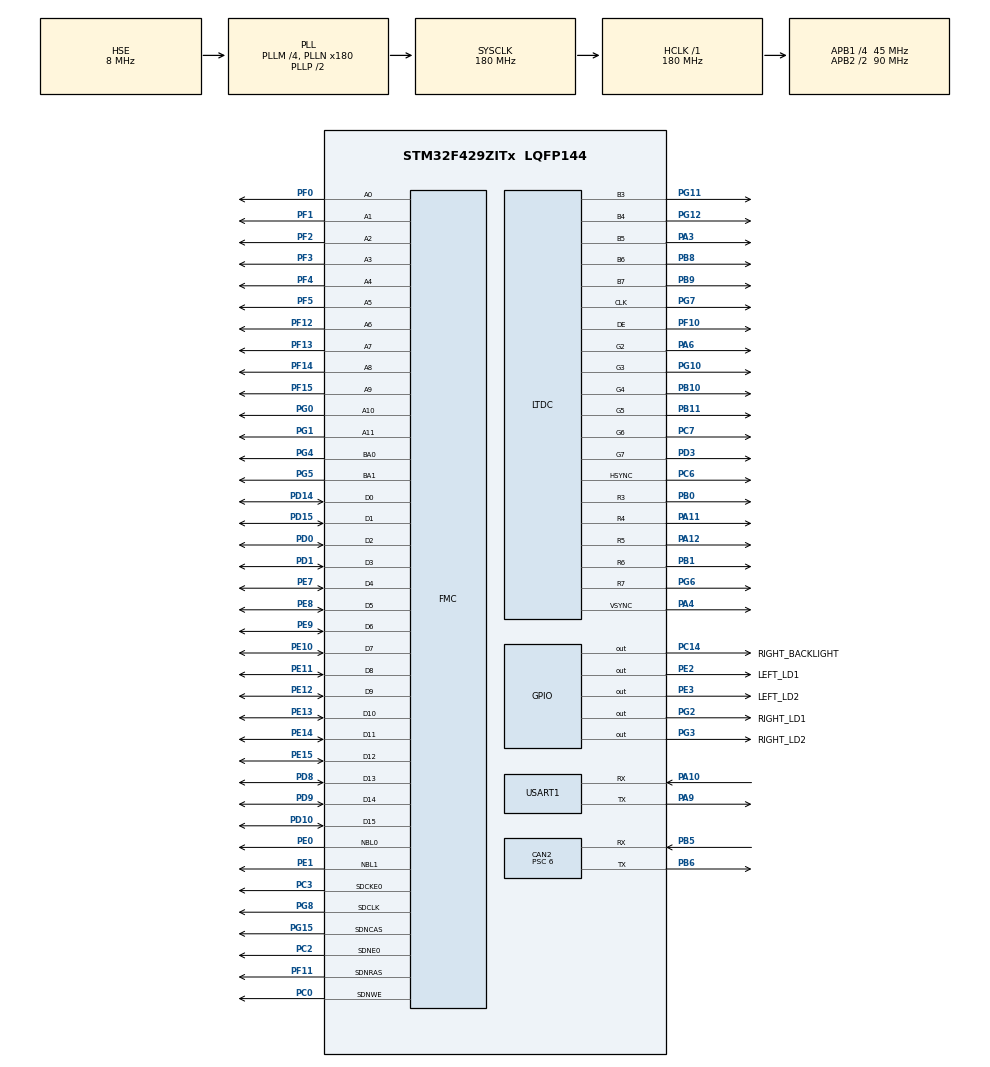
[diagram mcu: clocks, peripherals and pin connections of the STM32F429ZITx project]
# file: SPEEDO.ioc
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CAN2.ABOM=ENABLE
CAN2.BS1=CAN_BS1_12TQ
CAN2.BS2=CAN_BS2_2TQ
CAN2.CalculateTimeQuantum=133.33333333333331
CAN2.Prescaler=6
DMA2D.ColorMode=DMA2D_OUTPUT_RGB565
DMA2D.Mode=DMA2D_R2M
FMC.CASLatency1=FMC_SDRAM_CAS_LATENCY_3
FMC.ExitSelfRefreshDelay1=7
FMC.LoadToActiveDelay1=2
FMC.RPDelay1=2
FMC.RPDelay2=2
FMC.ReadPipeDelay1=FMC_SDRAM_RPIPE_DELAY_1
FMC.ReadPipeDelay2=FMC_SDRAM_RPIPE_DELAY_1
FMC.RowCycleDelay1=7
FMC.RowCycleDelay2=7
FMC.SDClockPeriod1=FMC_SDRAM_CLOCK_PERIOD_2
FMC.SDClockPeriod2=FMC_SDRAM_CLOCK_PERIOD_2
FMC.SelfRefreshTime1=4
FMC.WriteRecoveryTime1=2
FREERTOS.INCLUDE_vTaskDelayUntil=1
FREERTOS.Mutexes01=CanTxMutex,Dynamic,NULL;LogMutex,Dynamic,NULL
FREERTOS.Tasks01=ManagerTask,55,128,StartManagerTask,Default,NULL,Dynamic,NULL,NULL;DisplayTask,32,256,StartDisplayTask,As weak,NULL,Dynamic,NULL,NULL;CanTxTask,24,128,StartCanTxTask,Default,NULL,Dynamic,NULL,NULL;CanRxTask,40,128,StartCanRxTask,Default,NULL,Dynamic,NULL,NULL
FREERTOS.configTIMER_TASK_PRIORITY=6
FREERTOS.configTIMER_TASK_STACK_DEPTH=128
FREERTOS.configTOTAL_HEAP_SIZE=22360
FREERTOS.configUSE_COUNTING_SEMAPHORES=1
FREERTOS.configUSE_RECURSIVE_MUTEXES=1
FREERTOS.configUSE_TIMERS=0
IWDG.Prescaler=IWDG_PRESCALER_16
LTDC.ActiveH=240
LTDC.ActiveW=320
LTDC.Alpha_L0=255
LTDC.Alpha_L1=255
LTDC.BlendingFactor1_L0=LTDC_BLENDING_FACTOR1_PAxCA
LTDC.BlendingFactor1_L1=LTDC_BLENDING_FACTOR1_PAxCA
LTDC.BlendingFactor2_L0=LTDC_BLENDING_FACTOR2_PAxCA
LTDC.BlendingFactor2_L1=LTDC_BLENDING_FACTOR2_PAxCA
LTDC.FBStartAdress_L0=0xC0000000
LTDC.FBStartAdress_L1=0xC0400000
LTDC.HBP=43
LTDC.HFP=8
LTDC.HSync=4
LTDC.ImageHeight_L0=240
LTDC.ImageHeight_L1=240
LTDC.ImageWidth_L0=320
LTDC.ImageWidth_L1=320
LTDC.PixelFormat_L0=LTDC_PIXEL_FORMAT_RGB565
LTDC.PixelFormat_L1=LTDC_PIXEL_FORMAT_ARGB1555
LTDC.VBP=12
LTDC.VFP=8
LTDC.VSync=4
LTDC.WindowX1_L0=320
LTDC.WindowX1_L1=320
LTDC.WindowY1_L0=240
LTDC.WindowY1_L1=240
Mcu.Family=STM32F4
Mcu.Name=STM32F429ZITx
Mcu.Package=LQFP144
NVIC.CAN2_RX0_IRQn=true\:5\:0\:false\:false\:true\:true\:true\:true
NVIC.DMA2D_IRQn=true\:5\:0\:false\:false\:false\:true\:true\:false
NVIC.LTDC_IRQn=true\:5\:0\:false\:false\:true\:true\:true\:true
NVIC.PriorityGroup=NVIC_PRIORITYGROUP_4
NVIC.TIM6_DAC_IRQn=true\:0\:0\:false\:false\:true\:false\:false\:true
NVIC.TimeBase=TIM6_DAC_IRQn
NVIC.TimeBaseIP=TIM6
NVIC.USART1_IRQn=true\:5\:0\:false\:false\:true\:true\:true\:true
PA10.Mode=Asynchronous
PA10.Signal=USART1_RX
PA11.Mode=RGB565
PA11.Signal=LTDC_R4
PA12.Mode=RGB565
PA12.Signal=LTDC_R5
PA13.Mode=Trace_Asynchronous_SW
PA13.Signal=SYS_JTMS-SWDIO
PA14.Mode=Trace_Asynchronous_SW
PA14.Signal=SYS_JTCK-SWCLK
PA3.Mode=RGB565
PA3.Signal=LTDC_B5
PA4.Mode=RGB565
PA4.Signal=LTDC_VSYNC
PA6.Mode=RGB565
PA6.Signal=LTDC_G2
PA9.Mode=Asynchronous
PA9.Signal=USART1_TX
PB0.Mode=RGB565
PB0.Signal=LTDC_R3
PB1.Mode=RGB565
PB1.Signal=LTDC_R6
PB10.Mode=RGB565
PB10.Signal=LTDC_G4
PB11.Mode=RGB565
PB11.Signal=LTDC_G5
PB3.Mode=Trace_Asynchronous_SW
PB3.Signal=SYS_JTDO-SWO
PB5.Mode=Slave
PB5.Signal=CAN2_RX
PB6.Mode=Slave
PB6.Signal=CAN2_TX
PB8.Mode=RGB565
PB8.Signal=LTDC_B6
PB9.Mode=RGB565
PB9.Signal=LTDC_B7
PC0.Signal=FMC_SDNWE
PC14/OSC32_IN.GPIO_Label=RIGHT_BACKLIGHT
PC14/OSC32_IN.Signal=GPIO_Output
PC2.Mode=SdramChipSelect1_1
PC2.Signal=FMC_SDNE0
PC3.Mode=SdramChipSelect1_1
PC3.Signal=FMC_SDCKE0
PC6.Mode=RGB565
PC6.Signal=LTDC_HSYNC
PC7.Mode=RGB565
PC7.Signal=LTDC_G6
PD0.Signal=FMC_D2_DA2
PD1.Signal=FMC_D3_DA3
PD10.Signal=FMC_D15_DA15
PD14.Signal=FMC_D0_DA0
PD15.Signal=FMC_D1_DA1
PD3.Mode=RGB565
PD3.Signal=LTDC_G7
PD8.Signal=FMC_D13_DA13
PD9.Signal=FMC_D14_DA14
PE0.Signal=FMC_NBL0
PE1.Signal=FMC_NBL1
PE10.Signal=FMC_D7_DA7
PE11.Signal=FMC_D8_DA8
PE12.Signal=FMC_D9_DA9
PE13.Signal=FMC_D10_DA10
PE14.Signal=FMC_D11_DA11
PE15.Signal=FMC_D12_DA12
PE2.GPIO_Label=LEFT_LD1
PE2.Signal=GPIO_Output
PE3.GPIO_Label=LEFT_LD2
PE3.Signal=GPIO_Output
PE7.Signal=FMC_D4_DA4
PE8.Signal=FMC_D5_DA5
PE9.Signal=FMC_D6_DA6
PF0.Signal=FMC_A0
PF1.Signal=FMC_A1
PF10.Mode=RGB565
PF10.Signal=LTDC_DE
PF11.Signal=FMC_SDNRAS
PF12.Signal=FMC_A6
PF13.Signal=FMC_A7
PF14.Signal=FMC_A8
PF15.Signal=FMC_A9
PF2.Signal=FMC_A2
PF3.Signal=FMC_A3
PF4.Signal=FMC_A4
PF5.Signal=FMC_A5
PG0.Signal=FMC_A10
PG1.Signal=FMC_A11
PG10.Mode=RGB565
PG10.Signal=LTDC_G3
PG11.Mode=RGB565
PG11.Signal=LTDC_B3
PG12.Mode=RGB565
PG12.Signal=LTDC_B4
PG15.Signal=FMC_SDNCAS
PG2.GPIO_Label=RIGHT_LD1
PG2.Signal=GPIO_Output
PG3.GPIO_Label=RIGHT_LD2
PG3.Signal=GPIO_Output
PG4.Signal=FMC_A14_BA0
PG5.Signal=FMC_A15_BA1
PG6.Mode=RGB565
PG6.Signal=LTDC_R7
PG7.Mode=RGB565
PG7.Signal=LTDC_CLK
PG8.Signal=FMC_SDCLK
PH0/OSC_IN.Mode=HSE-External-Oscillator
PH0/OSC_IN.Signal=RCC_OSC_IN
PH1/OSC_OUT.Mode=HSE-External-Oscillator
PH1/OSC_OUT.Signal=RCC_OSC_OUT
ProjectManager.HeapSize=0x200
ProjectManager.StackSize=0x400
ProjectManager.TargetToolchain=STM32CubeIDE
RCC.48MHZClocksFreq_Value=90000000
RCC.AHBFreq_Value=180000000
RCC.APB1CLKDivider=RCC_HCLK_DIV4
RCC.APB1Freq_Value=45000000
RCC.APB1TimFreq_Value=90000000
RCC.APB2CLKDivider=RCC_HCLK_DIV2
RCC.APB2Freq_Value=90000000
RCC.APB2TimFreq_Value=180000000
RCC.CortexFreq_Value=180000000
RCC.HCLKFreq_Value=180000000
RCC.HSE_VALUE=8000000
RCC.HSI_VALUE=16000000
RCC.LSE_VALUE=32768
RCC.PLLM=4
RCC.PLLN=180
RCC.PLLSAIDivR=RCC_PLLSAIDIVR_4
RCC.PLLSAIN=60
RCC.PLLSAIR=5
RCC.PLLSourceVirtual=RCC_PLLSOURCE_HSE
RCC.PWREXT_OverDrive=PWREXT_OverDrive_ACTIVATED
RCC.PWR_Regulator_Voltage_Scale=PWR_REGULATOR_VOLTAGE_SCALE1
RCC.SYSCLKFreq_VALUE=180000000
RCC.SYSCLKSource=RCC_SYSCLKSOURCE_PLLCLK
RCC.VCOOutputFreq_Value=360000000
SH.FMC_A0.0=FMC_A0,12b-sda1
SH.FMC_A1.0=FMC_A1,12b-sda1
SH.FMC_A10.0=FMC_A10,12b-sda1
SH.FMC_A11.0=FMC_A11,12b-sda1
SH.FMC_A14_BA0.0=FMC_BA0,FourSdramBanks1
SH.FMC_A15_BA1.0=FMC_BA1,FourSdramBanks1
SH.FMC_A2.0=FMC_A2,12b-sda1
SH.FMC_A3.0=FMC_A3,12b-sda1
SH.FMC_A4.0=FMC_A4,12b-sda1
SH.FMC_A5.0=FMC_A5,12b-sda1
SH.FMC_A6.0=FMC_A6,12b-sda1
SH.FMC_A7.0=FMC_A7,12b-sda1
SH.FMC_A8.0=FMC_A8,12b-sda1
SH.FMC_A9.0=FMC_A9,12b-sda1
SH.FMC_D0_DA0.0=FMC_D0,sd-16b-d1
SH.FMC_D10_DA10.0=FMC_D10,sd-16b-d1
SH.FMC_D11_DA11.0=FMC_D11,sd-16b-d1
SH.FMC_D12_DA12.0=FMC_D12,sd-16b-d1
SH.FMC_D13_DA13.0=FMC_D13,sd-16b-d1
SH.FMC_D14_DA14.0=FMC_D14,sd-16b-d1
SH.FMC_D15_DA15.0=FMC_D15,sd-16b-d1
SH.FMC_D1_DA1.0=FMC_D1,sd-16b-d1
SH.FMC_D2_DA2.0=FMC_D2,sd-16b-d1
SH.FMC_D3_DA3.0=FMC_D3,sd-16b-d1
SH.FMC_D4_DA4.0=FMC_D4,sd-16b-d1
SH.FMC_D5_DA5.0=FMC_D5,sd-16b-d1
SH.FMC_D6_DA6.0=FMC_D6,sd-16b-d1
SH.FMC_D7_DA7.0=FMC_D7,sd-16b-d1
SH.FMC_D8_DA8.0=FMC_D8,sd-16b-d1
SH.FMC_D9_DA9.0=FMC_D9,sd-16b-d1
SH.FMC_NBL0.0=FMC_NBL0,Sd2ByteEnable1
SH.FMC_NBL1.0=FMC_NBL1,Sd2ByteEnable1
SH.FMC_SDCLK.0=FMC_SDCLK,12b-sda1
SH.FMC_SDNCAS.0=FMC_SDNCAS,12b-sda1
SH.FMC_SDNRAS.0=FMC_SDNRAS,12b-sda1
SH.FMC_SDNWE.0=FMC_SDNWE,12b-sda1
USART1.VirtualMode=VM_ASYNC
VP_CRC_VS_CRC.Mode=CRC_Activate
VP_DMA2D_VS_DMA2D.Mode=DMA2D_Activate
VP_FREERTOS_VS_CMSIS_V2.Mode=CMSIS_V2
VP_IWDG_VS_IWDG.Mode=IWDG_Activate
VP_SYS_VS_tim6.Mode=TIM6
board=custom

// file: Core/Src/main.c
/* USER CODE BEGIN Header */
/**
 ******************************************************************************
 * @file           : main.c
 * @brief          : Main program body
 ******************************************************************************
 * @attention
 *
 * <h2><center>&copy; Copyright (c) 2020 STMicroelectronics.
 * All rights reserved.</center></h2>
 *
 * This software component is licensed by ST under BSD 3-Clause license,
 * the "License"; You may not use this file except in compliance with the
 * License. You may obtain a copy of the License at:
 *                        opensource.org/licenses/BSD-3-Clause
 *
 ******************************************************************************
 */
/* USER CODE END Header */

#include "main.h"
#include "cmsis_os.h"

/* USER CODE BEGIN Includes */
#include "Libs/_guiapp.h"
#include "Drivers/_stemwin.h"
#include "Drivers/_canbus.h"
#include "Nodes/HMI1.h"
#include "Nodes/VCU.h"
/* USER CODE END Includes */

CAN_HandleTypeDef hcan2;

CRC_HandleTypeDef hcrc;

DMA2D_HandleTypeDef hdma2d;

IWDG_HandleTypeDef hiwdg;

LTDC_HandleTypeDef hltdc;

UART_HandleTypeDef huart1;

SDRAM_HandleTypeDef hsdram1;

/* Definitions for ManagerTask */
osThreadId_t ManagerTaskHandle;
const osThreadAttr_t ManagerTask_attributes = {
		.name = "ManagerTask",
		.priority = (osPriority_t) osPriorityRealtime7,
		.stack_size = 128 * 4
};
/* Definitions for DisplayTask */
osThreadId_t DisplayTaskHandle;
const osThreadAttr_t DisplayTask_attributes = {
		.name = "DisplayTask",
		.priority = (osPriority_t) osPriorityAboveNormal,
		.stack_size = 256 * 4
};
/* Definitions for CanTxTask */
osThreadId_t CanTxTaskHandle;
const osThreadAttr_t CanTxTask_attributes = {
		.name = "CanTxTask",
		.priority = (osPriority_t) osPriorityNormal,
		.stack_size = 128 * 4
};
/* Definitions for CanRxTask */
osThreadId_t CanRxTaskHandle;
const osThreadAttr_t CanRxTask_attributes = {
		.name = "CanRxTask",
		.priority = (osPriority_t) osPriorityHigh,
		.stack_size = 128 * 4
};
/* Definitions for CanTxMutex */
osMutexId_t CanTxMutexHandle;
const osMutexAttr_t CanTxMutex_attributes = {
		.name = "CanTxMutex"
};
/* Definitions for LogMutex */
osMutexId_t LogMutexHandle;
const osMutexAttr_t LogMutex_attributes = {
		.name = "LogMutex"
};
/* USER CODE BEGIN PV */
osEventFlagsId_t GlobalEventHandle;
/* USER CODE END PV */

void SystemClock_Config(void);
static void MX_GPIO_Init(void);
static void MX_CAN2_Init(void);
static void MX_CRC_Init(void);
void MX_DMA2D_Init(void);
void MX_FMC_Init(void);
static void MX_IWDG_Init(void);
void MX_LTDC_Init(void);
static void MX_USART1_UART_Init(void);
void StartManagerTask(void *argument);
void StartDisplayTask(void *argument);
void StartCanTxTask(void *argument);
void StartCanRxTask(void *argument);

/* USER CODE BEGIN 0 */
extern hmi1_t HMI1;
extern vcu_t VCU;
/* USER CODE END 0 */

int main(void)
{

	/* MCU Configuration--------------------------------------------------------*/

	/* Reset of all peripherals, Initializes the Flash interface and the Systick. */
	HAL_Init();

	/* Configure the system clock */
	SystemClock_Config();

	/* Initialize all configured peripherals */
	MX_GPIO_Init();
	MX_CAN2_Init();
	MX_CRC_Init();
	MX_IWDG_Init();
	MX_USART1_UART_Init();
	/* USER CODE BEGIN 2 */
	CANBUS_Init();
	GRAPHICS_HW_Init();
	GRAPHICS_Init();
	/* USER CODE END 2 */

	/* Init scheduler */
	osKernelInitialize();
	/* Create the mutex(es) */
	/* creation of CanTxMutex */
	CanTxMutexHandle = osMutexNew(&CanTxMutex_attributes);

	/* creation of LogMutex */
	LogMutexHandle = osMutexNew(&LogMutex_attributes);

	/* USER CODE BEGIN RTOS_QUEUES */
	/* add queues, ... */
	GlobalEventHandle = osEventFlagsNew(NULL);
	/* USER CODE END RTOS_QUEUES */

	/* Create the thread(s) */
	/* creation of ManagerTask */
	ManagerTaskHandle = osThreadNew(StartManagerTask, NULL, &ManagerTask_attributes);

	/* creation of DisplayTask */
	DisplayTaskHandle = osThreadNew(StartDisplayTask, NULL, &DisplayTask_attributes);

	/* creation of CanTxTask */
	CanTxTaskHandle = osThreadNew(StartCanTxTask, NULL, &CanTxTask_attributes);

	/* creation of CanRxTask */
	CanRxTaskHandle = osThreadNew(StartCanRxTask, NULL, &CanRxTask_attributes);

	/* Start scheduler */
	osKernelStart();

	/* We should never get here as control is now taken by the scheduler */
	/* Infinite loop */
	while (1)
	{

	}
}

void SystemClock_Config(void)
{
	RCC_OscInitTypeDef RCC_OscInitStruct = { 0 };
	RCC_ClkInitTypeDef RCC_ClkInitStruct = { 0 };
	RCC_PeriphCLKInitTypeDef PeriphClkInitStruct = { 0 };

	/** Configure the main internal regulator output voltage
	 */
	__HAL_RCC_PWR_CLK_ENABLE();
	__HAL_PWR_VOLTAGESCALING_CONFIG(PWR_REGULATOR_VOLTAGE_SCALE1);
	/** Initializes the CPU, AHB and APB busses clocks
	 */
	RCC_OscInitStruct.OscillatorType = RCC_OSCILLATORTYPE_LSI | RCC_OSCILLATORTYPE_HSE;
	RCC_OscInitStruct.HSEState = RCC_HSE_ON;
	RCC_OscInitStruct.LSIState = RCC_LSI_ON;
	RCC_OscInitStruct.PLL.PLLState = RCC_PLL_ON;
	RCC_OscInitStruct.PLL.PLLSource = RCC_PLLSOURCE_HSE;
	RCC_OscInitStruct.PLL.PLLM = 4;
	RCC_OscInitStruct.PLL.PLLN = 180;
	RCC_OscInitStruct.PLL.PLLP = RCC_PLLP_DIV2;
	RCC_OscInitStruct.PLL.PLLQ = 4;
	if (HAL_RCC_OscConfig(&RCC_OscInitStruct) != HAL_OK)
			{
		Error_Handler();
	}
	/** Activate the Over-Drive mode
	 */
	if (HAL_PWREx_EnableOverDrive() != HAL_OK)
			{
		Error_Handler();
	}
	/** Initializes the CPU, AHB and APB busses clocks
	 */
	RCC_ClkInitStruct.ClockType = RCC_CLOCKTYPE_HCLK | RCC_CLOCKTYPE_SYSCLK
			| RCC_CLOCKTYPE_PCLK1 | RCC_CLOCKTYPE_PCLK2;
	RCC_ClkInitStruct.SYSCLKSource = RCC_SYSCLKSOURCE_PLLCLK;
	RCC_ClkInitStruct.AHBCLKDivider = RCC_SYSCLK_DIV1;
	RCC_ClkInitStruct.APB1CLKDivider = RCC_HCLK_DIV4;
	RCC_ClkInitStruct.APB2CLKDivider = RCC_HCLK_DIV2;

	if (HAL_RCC_ClockConfig(&RCC_ClkInitStruct, FLASH_LATENCY_5) != HAL_OK)
			{
		Error_Handler();
	}
	PeriphClkInitStruct.PeriphClockSelection = RCC_PERIPHCLK_LTDC;
	PeriphClkInitStruct.PLLSAI.PLLSAIN = 60;
	PeriphClkInitStruct.PLLSAI.PLLSAIR = 5;
	PeriphClkInitStruct.PLLSAIDivR = RCC_PLLSAIDIVR_4;
	if (HAL_RCCEx_PeriphCLKConfig(&PeriphClkInitStruct) != HAL_OK)
			{
		Error_Handler();
	}
}

static void MX_CAN2_Init(void)
{

	hcan2.Instance = CAN2;
	hcan2.Init.Prescaler = 6;
	hcan2.Init.Mode = CAN_MODE_NORMAL;
	hcan2.Init.SyncJumpWidth = CAN_SJW_1TQ;
	hcan2.Init.TimeSeg1 = CAN_BS1_12TQ;
	hcan2.Init.TimeSeg2 = CAN_BS2_2TQ;
	hcan2.Init.TimeTriggeredMode = DISABLE;
	hcan2.Init.AutoBusOff = ENABLE;
	hcan2.Init.AutoWakeUp = DISABLE;
	hcan2.Init.AutoRetransmission = DISABLE;
	hcan2.Init.ReceiveFifoLocked = DISABLE;
	hcan2.Init.TransmitFifoPriority = DISABLE;
	if (HAL_CAN_Init(&hcan2) != HAL_OK)
			{
		Error_Handler();
	}

}

static void MX_CRC_Init(void)
{

	hcrc.Instance = CRC;
	if (HAL_CRC_Init(&hcrc) != HAL_OK)
			{
		Error_Handler();
	}

}

void MX_DMA2D_Init(void)
{

	hdma2d.Instance = DMA2D;
	hdma2d.Init.Mode = DMA2D_R2M;
	hdma2d.Init.ColorMode = DMA2D_OUTPUT_RGB565;
	hdma2d.Init.OutputOffset = 0;
	if (HAL_DMA2D_Init(&hdma2d) != HAL_OK)
			{
		Error_Handler();
	}

}

static void MX_IWDG_Init(void)
{

	hiwdg.Instance = IWDG;
	hiwdg.Init.Prescaler = IWDG_PRESCALER_16;
	hiwdg.Init.Reload = 4095;
	if (HAL_IWDG_Init(&hiwdg) != HAL_OK)
			{
		Error_Handler();
	}

}

void MX_LTDC_Init(void)
{

	LTDC_LayerCfgTypeDef pLayerCfg = { 0 };
	LTDC_LayerCfgTypeDef pLayerCfg1 = { 0 };

	hltdc.Instance = LTDC;
	hltdc.Init.HSPolarity = LTDC_HSPOLARITY_AL;
	hltdc.Init.VSPolarity = LTDC_VSPOLARITY_AL;
	hltdc.Init.DEPolarity = LTDC_DEPOLARITY_AL;
	hltdc.Init.PCPolarity = LTDC_PCPOLARITY_IPC;
	hltdc.Init.HorizontalSync = 3;
	hltdc.Init.VerticalSync = 3;
	hltdc.Init.AccumulatedHBP = 46;
	hltdc.Init.AccumulatedVBP = 15;
	hltdc.Init.AccumulatedActiveW = 366;
	hltdc.Init.AccumulatedActiveH = 255;
	hltdc.Init.TotalWidth = 374;
	hltdc.Init.TotalHeigh = 263;
	hltdc.Init.Backcolor.Blue = 0;
	hltdc.Init.Backcolor.Green = 0;
	hltdc.Init.Backcolor.Red = 0;
	if (HAL_LTDC_Init(&hltdc) != HAL_OK)
			{
		Error_Handler();
	}
	pLayerCfg.WindowX0 = 0;
	pLayerCfg.WindowX1 = 320;
	pLayerCfg.WindowY0 = 0;
	pLayerCfg.WindowY1 = 240;
	pLayerCfg.PixelFormat = LTDC_PIXEL_FORMAT_RGB565;
	pLayerCfg.Alpha = 255;
	pLayerCfg.Alpha0 = 0;
	pLayerCfg.BlendingFactor1 = LTDC_BLENDING_FACTOR1_PAxCA;
	pLayerCfg.BlendingFactor2 = LTDC_BLENDING_FACTOR2_PAxCA;
	pLayerCfg.FBStartAdress = 0xC0000000;
	pLayerCfg.ImageWidth = 320;
	pLayerCfg.ImageHeight = 240;
	pLayerCfg.Backcolor.Blue = 0;
	pLayerCfg.Backcolor.Green = 0;
	pLayerCfg.Backcolor.Red = 0;
	if (HAL_LTDC_ConfigLayer(&hltdc, &pLayerCfg, 0) != HAL_OK)
			{
		Error_Handler();
	}
	pLayerCfg1.WindowX0 = 0;
	pLayerCfg1.WindowX1 = 320;
	pLayerCfg1.WindowY0 = 0;
	pLayerCfg1.WindowY1 = 240;
	pLayerCfg1.PixelFormat = LTDC_PIXEL_FORMAT_ARGB1555;
	pLayerCfg1.Alpha = 255;
	pLayerCfg1.Alpha0 = 0;
	pLayerCfg1.BlendingFactor1 = LTDC_BLENDING_FACTOR1_PAxCA;
	pLayerCfg1.BlendingFactor2 = LTDC_BLENDING_FACTOR2_PAxCA;
	pLayerCfg1.FBStartAdress = 0xC0400000;
	pLayerCfg1.ImageWidth = 320;
	pLayerCfg1.ImageHeight = 240;
	pLayerCfg1.Backcolor.Blue = 0;
	pLayerCfg1.Backcolor.Green = 0;
	pLayerCfg1.Backcolor.Red = 0;
	if (HAL_LTDC_ConfigLayer(&hltdc, &pLayerCfg1, 1) != HAL_OK)
			{
		Error_Handler();
	}

}

static void MX_USART1_UART_Init(void)
{

	huart1.Instance = USART1;
	huart1.Init.BaudRate = 115200;
	huart1.Init.WordLength = UART_WORDLENGTH_8B;
	huart1.Init.StopBits = UART_STOPBITS_1;
	huart1.Init.Parity = UART_PARITY_NONE;
	huart1.Init.Mode = UART_MODE_TX_RX;
	huart1.Init.HwFlowCtl = UART_HWCONTROL_NONE;
	huart1.Init.OverSampling = UART_OVERSAMPLING_16;
	if (HAL_UART_Init(&huart1) != HAL_OK)
			{
		Error_Handler();
	}

}

/* FMC initialization function */
void MX_FMC_Init(void)
{

	FMC_SDRAM_TimingTypeDef SdramTiming = { 0 };

	/** Perform the SDRAM1 memory initialization sequence
	 */
	hsdram1.Instance = FMC_SDRAM_DEVICE;
	/* hsdram1.Init */
	hsdram1.Init.SDBank = FMC_SDRAM_BANK1;
	hsdram1.Init.ColumnBitsNumber = FMC_SDRAM_COLUMN_BITS_NUM_8;
	hsdram1.Init.RowBitsNumber = FMC_SDRAM_ROW_BITS_NUM_12;
	hsdram1.Init.MemoryDataWidth = FMC_SDRAM_MEM_BUS_WIDTH_16;
	hsdram1.Init.InternalBankNumber = FMC_SDRAM_INTERN_BANKS_NUM_4;
	hsdram1.Init.CASLatency = FMC_SDRAM_CAS_LATENCY_3;
	hsdram1.Init.WriteProtection = FMC_SDRAM_WRITE_PROTECTION_DISABLE;
	hsdram1.Init.SDClockPeriod = FMC_SDRAM_CLOCK_PERIOD_2;
	hsdram1.Init.ReadBurst = FMC_SDRAM_RBURST_DISABLE;
	hsdram1.Init.ReadPipeDelay = FMC_SDRAM_RPIPE_DELAY_1;
	/* SdramTiming */
	SdramTiming.LoadToActiveDelay = 2;
	SdramTiming.ExitSelfRefreshDelay = 7;
	SdramTiming.SelfRefreshTime = 4;
	SdramTiming.RowCycleDelay = 7;
	SdramTiming.WriteRecoveryTime = 2;
	SdramTiming.RPDelay = 2;
	SdramTiming.RCDDelay = 16;

	if (HAL_SDRAM_Init(&hsdram1, &SdramTiming) != HAL_OK)
			{
		Error_Handler();
	}

}

static void MX_GPIO_Init(void)
{
	GPIO_InitTypeDef GPIO_InitStruct = { 0 };

	/* GPIO Ports Clock Enable */
	__HAL_RCC_GPIOE_CLK_ENABLE();
	__HAL_RCC_GPIOC_CLK_ENABLE();
	__HAL_RCC_GPIOF_CLK_ENABLE();
	__HAL_RCC_GPIOH_CLK_ENABLE();
	__HAL_RCC_GPIOA_CLK_ENABLE();
	__HAL_RCC_GPIOB_CLK_ENABLE();
	__HAL_RCC_GPIOG_CLK_ENABLE();
	__HAL_RCC_GPIOD_CLK_ENABLE();

	/*Configure GPIO pin Output Level */
	HAL_GPIO_WritePin(GPIOE, LEFT_LD1_Pin | LEFT_LD2_Pin, GPIO_PIN_RESET);

	/*Configure GPIO pin Output Level */
	HAL_GPIO_WritePin(RIGHT_BACKLIGHT_GPIO_Port, RIGHT_BACKLIGHT_Pin, GPIO_PIN_RESET);

	/*Configure GPIO pin Output Level */
	HAL_GPIO_WritePin(GPIOG, RIGHT_LD1_Pin | RIGHT_LD2_Pin, GPIO_PIN_RESET);

	/*Configure GPIO pins : LEFT_LD1_Pin LEFT_LD2_Pin */
	GPIO_InitStruct.Pin = LEFT_LD1_Pin | LEFT_LD2_Pin;
	GPIO_InitStruct.Mode = GPIO_MODE_OUTPUT_PP;
	GPIO_InitStruct.Pull = GPIO_NOPULL;
	GPIO_InitStruct.Speed = GPIO_SPEED_FREQ_LOW;
	HAL_GPIO_Init(GPIOE, &GPIO_InitStruct);

	/*Configure GPIO pins : PE4 PE5 PE6 */
	GPIO_InitStruct.Pin = GPIO_PIN_4 | GPIO_PIN_5 | GPIO_PIN_6;
	GPIO_InitStruct.Mode = GPIO_MODE_ANALOG;
	GPIO_InitStruct.Pull = GPIO_NOPULL;
	HAL_GPIO_Init(GPIOE, &GPIO_InitStruct);

	/*Configure GPIO pins : PC13 PC15 PC1 PC4
	 PC5 PC8 PC9 PC10
	 PC11 PC12 */
	GPIO_InitStruct.Pin = GPIO_PIN_13 | GPIO_PIN_15 | GPIO_PIN_1 | GPIO_PIN_4
			| GPIO_PIN_5 | GPIO_PIN_8 | GPIO_PIN_9 | GPIO_PIN_10
			| GPIO_PIN_11 | GPIO_PIN_12;
	GPIO_InitStruct.Mode = GPIO_MODE_ANALOG;
	GPIO_InitStruct.Pull = GPIO_NOPULL;
	HAL_GPIO_Init(GPIOC, &GPIO_InitStruct);

	/*Configure GPIO pin : RIGHT_BACKLIGHT_Pin */
	GPIO_InitStruct.Pin = RIGHT_BACKLIGHT_Pin;
	GPIO_InitStruct.Mode = GPIO_MODE_OUTPUT_PP;
	GPIO_InitStruct.Pull = GPIO_NOPULL;
	GPIO_InitStruct.Speed = GPIO_SPEED_FREQ_LOW;
	HAL_GPIO_Init(RIGHT_BACKLIGHT_GPIO_Port, &GPIO_InitStruct);

	/*Configure GPIO pins : PF6 PF7 PF8 PF9 */
	GPIO_InitStruct.Pin = GPIO_PIN_6 | GPIO_PIN_7 | GPIO_PIN_8 | GPIO_PIN_9;
	GPIO_InitStruct.Mode = GPIO_MODE_ANALOG;
	GPIO_InitStruct.Pull = GPIO_NOPULL;
	HAL_GPIO_Init(GPIOF, &GPIO_InitStruct);

	/*Configure GPIO pins : PA0 PA1 PA2 PA5
	 PA7 PA8 PA15 */
	GPIO_InitStruct.Pin = GPIO_PIN_0 | GPIO_PIN_1 | GPIO_PIN_2 | GPIO_PIN_5
			| GPIO_PIN_7 | GPIO_PIN_8 | GPIO_PIN_15;
	GPIO_InitStruct.Mode = GPIO_MODE_ANALOG;
	GPIO_InitStruct.Pull = GPIO_NOPULL;
	HAL_GPIO_Init(GPIOA, &GPIO_InitStruct);

	/*Configure GPIO pins : PB2 PB12 PB13 PB14
	 PB15 PB4 PB7 */
	GPIO_InitStruct.Pin = GPIO_PIN_2 | GPIO_PIN_12 | GPIO_PIN_13 | GPIO_PIN_14
			| GPIO_PIN_15 | GPIO_PIN_4 | GPIO_PIN_7;
	GPIO_InitStruct.Mode = GPIO_MODE_ANALOG;
	GPIO_InitStruct.Pull = GPIO_NOPULL;
	HAL_GPIO_Init(GPIOB, &GPIO_InitStruct);

	/*Configure GPIO pins : PD11 PD12 PD13 PD2
	 PD4 PD5 PD6 PD7 */
	GPIO_InitStruct.Pin = GPIO_PIN_11 | GPIO_PIN_12 | GPIO_PIN_13 | GPIO_PIN_2
			| GPIO_PIN_4 | GPIO_PIN_5 | GPIO_PIN_6 | GPIO_PIN_7;
	GPIO_InitStruct.Mode = GPIO_MODE_ANALOG;
	GPIO_InitStruct.Pull = GPIO_NOPULL;
	HAL_GPIO_Init(GPIOD, &GPIO_InitStruct);

	/*Configure GPIO pins : RIGHT_LD1_Pin RIGHT_LD2_Pin */
	GPIO_InitStruct.Pin = RIGHT_LD1_Pin | RIGHT_LD2_Pin;
	GPIO_InitStruct.Mode = GPIO_MODE_OUTPUT_PP;
	GPIO_InitStruct.Pull = GPIO_NOPULL;
	GPIO_InitStruct.Speed = GPIO_SPEED_FREQ_LOW;
	HAL_GPIO_Init(GPIOG, &GPIO_InitStruct);

	/*Configure GPIO pins : PG9 PG13 PG14 */
	GPIO_InitStruct.Pin = GPIO_PIN_9 | GPIO_PIN_13 | GPIO_PIN_14;
	GPIO_InitStruct.Mode = GPIO_MODE_ANALOG;
	GPIO_InitStruct.Pull = GPIO_NOPULL;
	HAL_GPIO_Init(GPIOG, &GPIO_InitStruct);

}

void StartManagerTask(void *argument)
{
	/* USER CODE BEGIN 5 */
	TickType_t lastWake;

	// Reset database
	_ResetSystem();

	// Release other threads
	osEventFlagsSet(GlobalEventHandle, EVENT_READY);

	/* Infinite loop */
	for (;;) {
		lastWake = osKernelGetTickCount();

		// Feed the dog
		HAL_IWDG_Refresh(&hiwdg);

		// Dummy Data
		//		DB.mcu.rpm += MCU_RPM_MAX / 1000;
		//		DB.vcu.odometer++;
		//
		//		if (osKernelGetTickCount() % 500 == 0) {
		//			DB.hmi1.status.sein_left = !DB.hmi1.status.sein_left;
		//			DB.hmi1.status.keyless = !DB.hmi1.status.keyless;
		//			DB.hmi1.status.mirror = !DB.hmi1.status.mirror;
		//		}
		//		DB.vcu.speed++;

		// Periodic interval
		osDelayUntil(lastWake + pdMS_TO_TICKS(500));
	}
	/* USER CODE END 5 */
}

__weak void StartDisplayTask(void *argument)
{
	for (;;)
			{
		osDelay(1);
	}
}

void StartCanTxTask(void *argument)
{
	/* USER CODE BEGIN StartCanTxTask */
	TickType_t lastWake;

	// wait until ManagerTask done
	osEventFlagsWait(GlobalEventHandle, EVENT_READY, osFlagsNoClear, osWaitForever);

	/* Infinite loop */
	for (;;) {
		lastWake = osKernelGetTickCount();

		// Send to CAN
		HMI1.can.t.Heartbeat();

		// Periodic interval
		osDelayUntil(lastWake + pdMS_TO_TICKS(500));
	}
	/* USER CODE END StartCanTxTask */
}

void StartCanRxTask(void *argument)
{
	/* USER CODE BEGIN StartCanRxTask */
	uint32_t notif;
	uint8_t related;

	// wait until ManagerTask done
	osEventFlagsWait(GlobalEventHandle, EVENT_READY, osFlagsNoClear, osWaitForever);

	/* Infinite loop */
	for (;;) {
		// check if has new can message
		notif = osThreadFlagsWait(EVT_MASK, osFlagsWaitAny, osWaitForever);
		if (_RTOS_ValidThreadFlag(notif)) {
			// proceed event
			if (notif & EVT_CAN_RX_IT) {
				related = 1;
				// handle message
				switch (CANBUS_ReadID()) {
					case CAND_VCU_SWITCH:
						VCU.can.r.SwitchModeControl();
						break;
					case CAND_VCU_SELECT_SET:
						VCU.can.r.MixedData();
						break;
					case CAND_VCU_TRIP_MODE:
						VCU.can.r.SubTripData();
						break;
					default:
						related = 0;
						break;
				}

				// notify GUI thread
				if (related) {
					osThreadFlagsSet(DisplayTaskHandle, EVT_DISPLAY_UPDATE);
				}
			}
		}
	}
	/* USER CODE END StartCanRxTask */
}

void HAL_TIM_PeriodElapsedCallback(TIM_HandleTypeDef *htim)
{
	if (htim->Instance == TIM6) {
		HAL_IncTick();
	}
}

void Error_Handler(void)
{
	/* USER CODE BEGIN Error_Handler_Debug */
	/* User can add his own implementation to report the HAL error return state */
	while (1) {
		_LedToggle();
		HAL_Delay(50);
	};
	/* USER CODE END Error_Handler_Debug */
}

/************************ (C) COPYRIGHT STMicroelectronics *****END OF FILE****/
